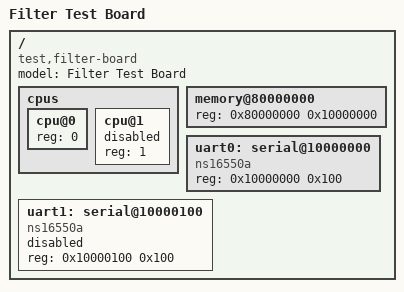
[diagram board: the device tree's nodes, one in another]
/dts-v1/;

/ {
	model = "Filter Test Board";
	compatible = "test,filter-board";

	cpus {
		#address-cells = <1>;
		#size-cells = <0>;

		cpu@0 {
			device_type = "cpu";
			reg = <0>;
			status = "okay";
		};

		cpu@1 {
			device_type = "cpu";
			reg = <1>;
			status = "disabled";
		};
	};

	memory@80000000 {
		device_type = "memory";
		reg = <0x80000000 0x10000000>;
	};

	uart0: serial@10000000 {
		compatible = "ns16550a";
		reg = <0x10000000 0x100>;
		status = "okay";
	};

	uart1: serial@10000100 {
		compatible = "ns16550a";
		reg = <0x10000100 0x100>;
		status = "disabled";
	};
};
